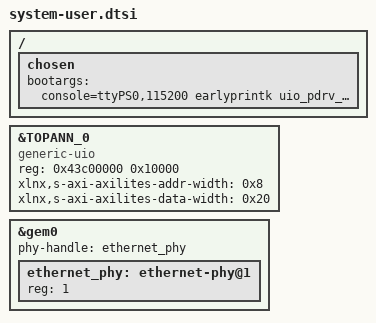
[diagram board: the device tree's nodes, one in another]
/include/ "system-conf.dtsi"
/ {

	chosen {
		bootargs = "console=ttyPS0,115200 earlyprintk uio_pdrv_genirq.of_id=generic-uio root=/dev/mmcblk0p2 rw rootwait";
	};


};

&TOPANN_0  {
			compatible = "generic-uio";
			reg = <0x43c00000 0x10000>;
			xlnx,s-axi-axilites-addr-width = <0x8>;
			xlnx,s-axi-axilites-data-width = <0x20>;
		};

&gem0 {
	phy-handle = <&ethernet_phy>;
/*	phy-reset-gpio = <&axi_gpio_eth 0 0>;
	phy-reset-active-low;	
	phy-reset-duration = <10>; */
	ethernet_phy: ethernet-phy@1 { /* rtl8211e-vl */
		reg = <1>;
		device_type = "ethernet-phy";
	};
};
